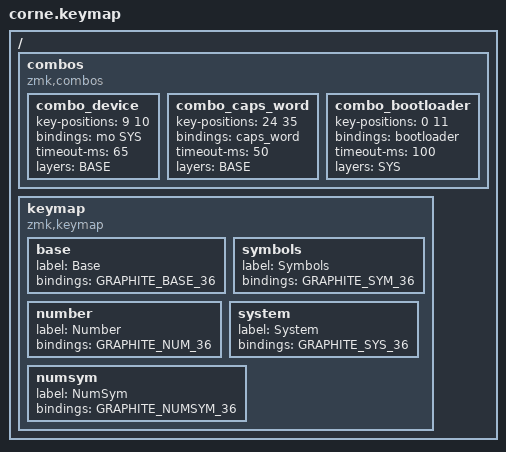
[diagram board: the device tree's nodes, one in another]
/*
 * Copyright (c) 2020 The ZMK Contributors
 *
 * SPDX-License-Identifier: MIT
 */

#include <behaviors.dtsi>
#include <dt-bindings/zmk/keys.h>
#include <dt-bindings/zmk/bt.h>
#include <dt-bindings/zmk/outputs.h>
#include <dt-bindings/zmk/rgb.h>

#include "graphite.dtsi"

/ {
    combos {
        compatible = "zmk,combos";

        // U+J: hold for Device layer
        combo_device {
            key-positions = <9 10>;
            bindings = <&mo SYS>;
            timeout-ms = <65>;
            layers = <BASE>;
        };

        // both shifts: caps word
        combo_caps_word {
            key-positions = <24 35>;
            bindings = <&caps_word>;
            timeout-ms = <50>;
            layers = <BASE>;
        };

        // outer corners: bootloader in device layer
        combo_bootloader {
            key-positions = <0 11>;
            bindings = <&bootloader>;
            timeout-ms = <100>;
            layers = <SYS>;
        };
    };

    keymap {
        compatible = "zmk,keymap";

        base {
            label = "Base";
            bindings = < GRAPHITE_BASE_36 >;
        };

        symbols {
            label = "Symbols";
            bindings = < GRAPHITE_SYM_36 >;
        };

        number {
            label = "Number";
            bindings = < GRAPHITE_NUM_36 >;
        };

        system {
            label = "System";
            bindings = < GRAPHITE_SYS_36 >;
        };

        numsym {
            label = "NumSym";
            bindings = < GRAPHITE_NUMSYM_36 >;
        };

    };
};
